# BL616/BL618 register map
Vendor: Bouffalo Lab; File version: 1.0
Registers are 32-bit, read-write, reset 0x0 unless marked. A register's access mark holds for its fields unless they carry their own. Offsets are from the block's base; [hi:lo] are bit positions; lines under a group give offsets from that group; {n}, {i} and the like mark numbered series.

## PWM — Pulse-Width Modulation module
Base 0x2000A400
0x00 interrupt_config — Interrupt state and clear register
{0x40+0x40*i} group[{i}] (i=0..1) group — Pulse-Width Modulation channel group
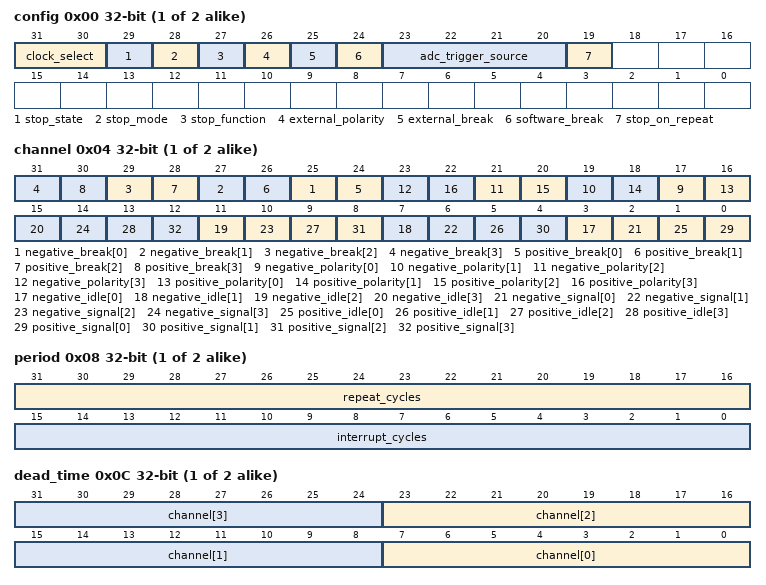
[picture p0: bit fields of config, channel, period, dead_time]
  0x00 config — Peripheral group configuration
    [31:30] clock_select — Select group clock source
      0=xtal (External crystal as clock source); 1=bclk (Bus clock as clock source); 2=f32k (32-kHz clock source)
    [29] stop_state — Is this peripheral stopped?
    [28] stop_mode — Mode to stop this peripheral
    [27] stop_function — Enable or disable stop function
    [26] external_polarity — Polarity for external pin break function
    [25] external_break — Enable external pin signal break
    [24] software_break — Enable software signal break
    [23:20] adc_trigger_source — Select channel in Analog-to-Digital Converter to interact with this peripheral **This field only works with PWM0.** PWM1 does not have this feature.
    [19] stop_on_repeat — Enable or disable stop on one repeat cycle completed
  0x04 channel — Channel configuration register
    [2n+25] negative_break[{n}] (n=0..3) — Break state on negative signal of this channel
    [2n+24] positive_break[{n}] (n=0..3) — Break state on positive signal of this channel
    [2n+17] negative_polarity[{n}] (n=0..3) — Polarity of negative signal
    [2n+16] positive_polarity[{n}] (n=0..3) — Polarity of positive signal
    [4n+3] negative_idle[{n}] (n=0..3) — Idle state of negative signal
    [4n+2] negative_signal[{n}] (n=0..3) — Enable or disable negative signal for channel
    [4n+1] positive_idle[{n}] (n=0..3) — Idle state of positive signal
    [4n] positive_signal[{n}] (n=0..3) — Enable or disable positive signal for channel
  0x08 period — Pulse clock period register
    [31:16] repeat_cycles — How many clock cycles a Pulse-Width Modulation cycle includes
    [15:0] interrupt_cycles — If internal counter reaches this cycle count, it interrupts
  0x0C dead_time — Dead time for each channel
    [8n+7:8n] channel[{n}] (n=0..3) — Dead time for each channel in cycles
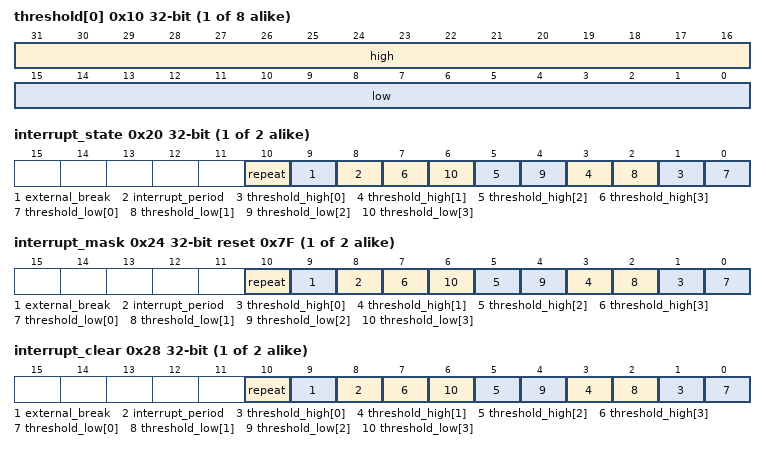
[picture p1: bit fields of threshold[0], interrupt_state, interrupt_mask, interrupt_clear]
  {0x10+4j} threshold[{j}] (j=0..3) — Channel internal counter threshold
    [31:16] high — Highest value for internal counter that sets positive signal to 1 and negative to 0
    [15:0] low — Lowest value for internal counter that sets positive signal to 1 and negative to 0
  0x20 interrupt_state ro
    [all] fields
      1=has_interrupt; 0=No interrupt occurred
    [10] repeat — Peripheral group have completed one repeat cycle
    [9] external_break — External break signal occurred
    [8] interrupt_period — Intenal counter for channel have exceeded interrupt cycle threshold
    [2n+1] threshold_high[{n}] (n=0..3) — Intenal counter for channel have exceeded high threshold
    [2n] threshold_low[{n}] (n=0..3) — Intenal counter for channel have exceeded low threshold
  0x24 interrupt_mask reset 0x7F
    [all] fields
      1=Mask interrupt; 0=Unmask interrupt
    [10] repeat — Peripheral group have completed one repeat cycle
    [9] external_break — External break signal occurred
    [8] interrupt_period — Intenal counter for channel have exceeded interrupt cycle threshold
    [2n+1] threshold_high[{n}] (n=0..3) — Intenal counter for channel have exceeded high threshold
    [2n] threshold_low[{n}] (n=0..3) — Intenal counter for channel have exceeded low threshold
  0x28 interrupt_clear wo — Clear interrupt register
    [all] fields
      1=clear (Write 1 to clear interrupt state)
    [10] repeat — Peripheral group have completed one repeat cycle
    [9] external_break — External break signal occurred
    [8] interrupt_period — Intenal counter for channel have exceeded interrupt cycle threshold
    [2n+1] threshold_high[{n}] (n=0..3) — Intenal counter for channel have exceeded high threshold
    [2n] threshold_low[{n}] (n=0..3) — Intenal counter for channel have exceeded low threshold
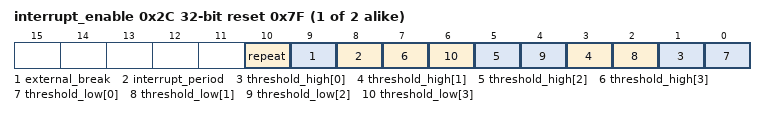
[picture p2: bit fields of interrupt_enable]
  0x2C interrupt_enable reset 0x7F
    [all] fields
      1=Enable interrupt; 0=Disable interrupt
    [10] repeat — Peripheral group have completed one repeat cycle
    [9] external_break — External break signal occurred
    [8] interrupt_period — Intenal counter for channel have exceeded interrupt cycle threshold
    [2n+1] threshold_high[{n}] (n=0..3) — Intenal counter for channel have exceeded high threshold
    [2n] threshold_low[{n}] (n=0..3) — Intenal counter for channel have exceeded low threshold
